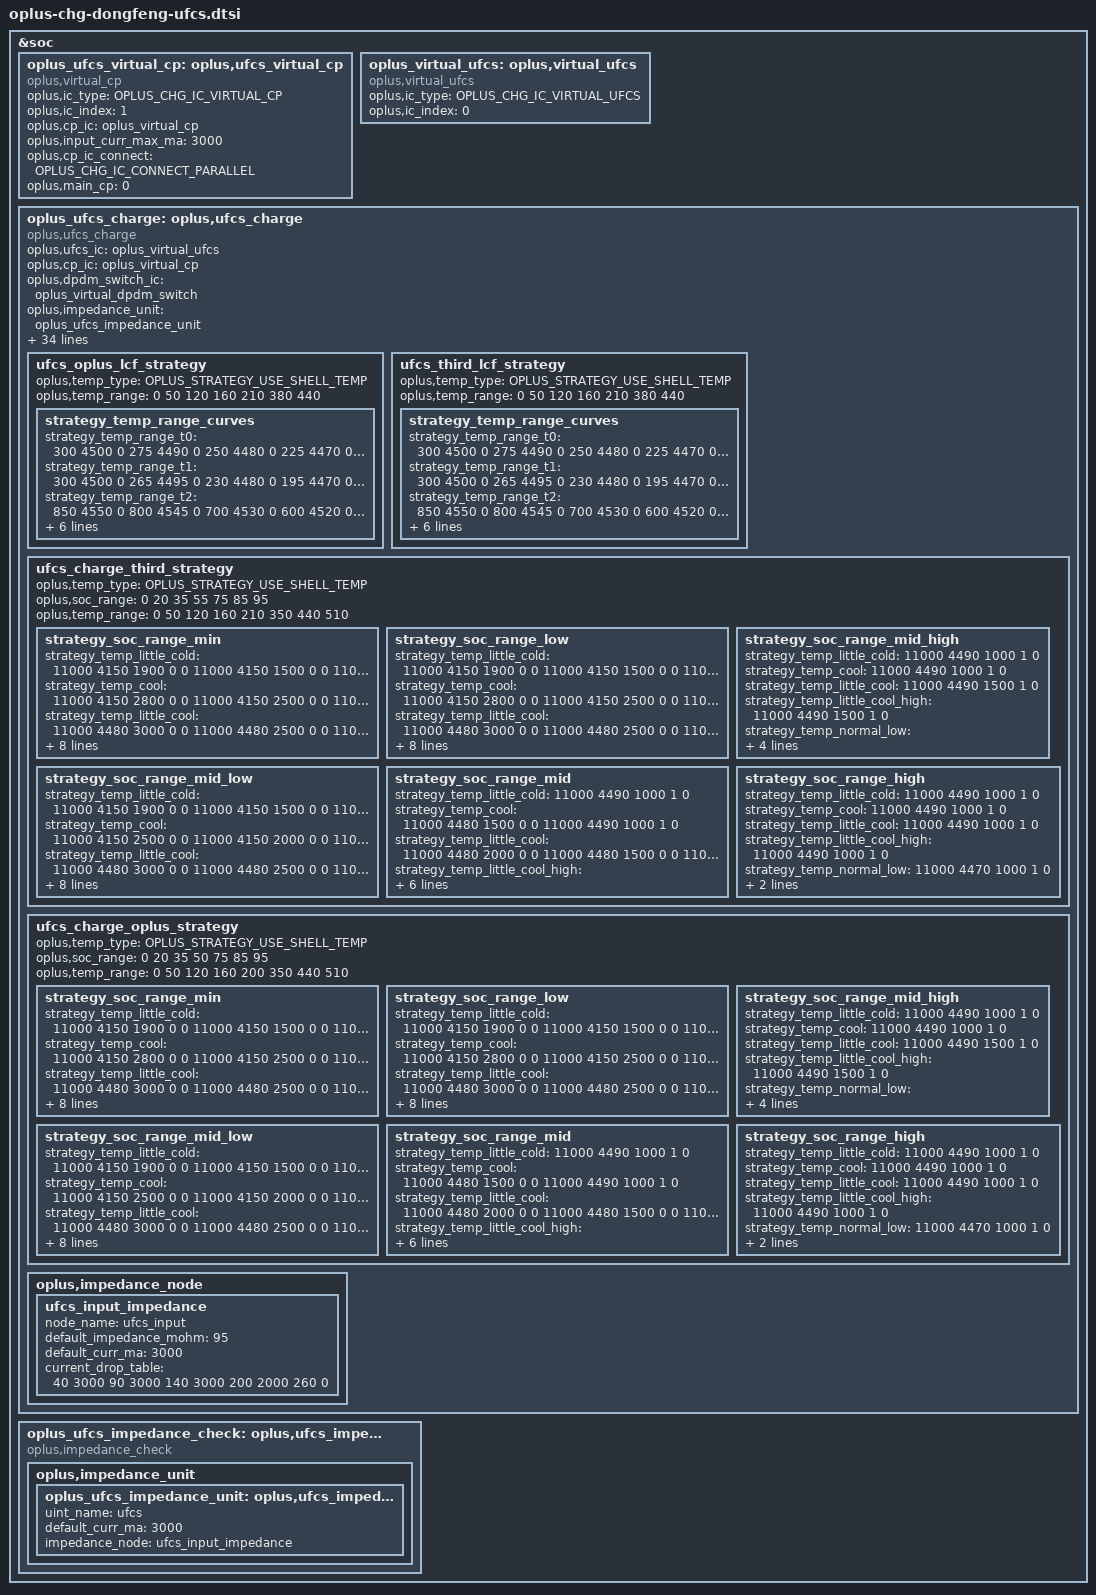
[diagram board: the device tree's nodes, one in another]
//ifdef OPLUS_FEATURE_CHG_BASIC
//BSP.CHG.Basic, 2024/08/03,  Add for charging

#include <dt-bindings/iio/qcom,spmi-adc5-gen3-pmxr2230.h>
#include <dt-bindings/iio/qcom,spmi-adc5-gen3-pmiv0104.h>
#include <dt-bindings/iio/qcom,spmi-adc5-gen3-pmk8550.h>

#include "../oplus-chg-8650.h.dtsi"

&soc {
	oplus_ufcs_virtual_cp: oplus,ufcs_virtual_cp {
		compatible = "oplus,virtual_cp";

		oplus,ic_type = <OPLUS_CHG_IC_VIRTUAL_CP>;
		oplus,ic_index = <1>;

		oplus,cp_ic = <&oplus_virtual_cp>;
		oplus,input_curr_max_ma = <3000>;

		oplus,cp_ic_connect = <OPLUS_CHG_IC_CONNECT_PARALLEL>;
		oplus,main_cp = <0>;
	};

	oplus_virtual_ufcs: oplus,virtual_ufcs {
		compatible = "oplus,virtual_ufcs";

		oplus,ic_type = <OPLUS_CHG_IC_VIRTUAL_UFCS>;
		oplus,ic_index = <0>;
	};

	oplus_ufcs_charge: oplus,ufcs_charge {
		compatible = "oplus,ufcs_charge";
		oplus,ufcs_ic = <&oplus_virtual_ufcs>;
		oplus,cp_ic = <&oplus_virtual_cp>;
		oplus,dpdm_switch_ic = <&oplus_virtual_dpdm_switch>;

		oplus,impedance_unit = <&oplus_ufcs_impedance_unit>;

		oplus,target_vbus_mv = <11000>;
		oplus,curr_max_ma = <3000>;

		oplus,ufcs_warm_allow_vol = <4000>;
		oplus,ufcs_warm_allow_soc = <55>;
		oplus,ufcs_strategy_normal_current = <3000>;//6A
		oplus,ufcs_over_high_or_low_current = <3000>;
		oplus,ufcs_timeout_third = <15068>;
		oplus,ufcs_timeout_oplus = <15068>;
		oplus,ufcs_ibat_over_third = <7400>;
		oplus,ufcs_ibat_over_oplus = <7400>;
		oplus,ufcs_full_cool_sw_vbat = <4490>;
		oplus,ufcs_full_normal_sw_vbat = <4490>;
		oplus,ufcs_full_normal_hw_vbat = <4500>;
		oplus,ufcs_full_ffc_vbat = <4485>;
		oplus,ufcs_full_warm_vbat = <4130>;
		oplus,ufcs_full_cool_sw_vbat_third = <4490>;
		oplus,ufcs_full_normal_sw_vbat_third= <4490>;
		oplus,ufcs_full_normal_hw_vbat_third = <4500>;
		oplus,ufcs_current_change_timeout = <100>;
		oplus,ufcs_strategy_batt_high_temp = <410 420 430 400 410 420>;
		oplus,ufcs_strategy_high_current = <3000 3000 2000 3000 3000 3000>;
		oplus,ufcs_little_cool_high_temp = <210>;
		oplus,curve_strategy_name = "pps_ufcs_curve_v2";
		oplus_spec,ufcs_high_soc = <95>;
		oplus,ufcs_charge_strategy_soc = <0 20 35 55 75 85 95>;
		oplus,ufcs_charge_strategy_temp = <0 50 120 160 350 440 510>;

		oplus,plc_strategy-data = <&oplus_ufcs_step_strategy &third_ufcs_simple_strategy>;
		oplus,plc_strategy-names = "default", "third";

		ufcs_oplus_lcf_strategy {
			oplus,temp_type = <OPLUS_STRATEGY_USE_SHELL_TEMP>;
			oplus,temp_range = <0 50 120 160 210 380 440>;
			strategy_temp_range_curves {
				strategy_temp_range_t0 =	<300 4500 0
								275 4490 0
								250 4480 0
								225 4470 0
								200 4460 1>;
				strategy_temp_range_t1 =	<300 4500 0
								265 4495 0
								230 4480 0
								195 4470 0
								160 4460 1>;
				strategy_temp_range_t2 =	<850 4550 0
								800 4545 0
								700 4530 0
								600 4520 0
								450 4510 1>;
				strategy_temp_range_t3 =	<1350 4550 0
								1300 4545 0
								1200 4530 0
								1100  4520 0
								950  4510 1>;
				strategy_temp_range_t4 =	<1350 4550 0
								1300 4545 0
								1200 4530 0
								1100 4520 0
								950 4510 1>;
				strategy_temp_range_t5 =	<2100 4550 0
								2050 4545 0
								1950 4530 0
								1850 4520 0
								1700 4510 1>;
			};
		};
		ufcs_third_lcf_strategy {
			oplus,temp_type = <OPLUS_STRATEGY_USE_SHELL_TEMP>;
			oplus,temp_range = <0 50 120 160 210 380 440>;
			strategy_temp_range_curves {
				strategy_temp_range_t0 =	<300 4500 0
								275 4490 0
								250 4480 0
								225 4470 0
								200 4460 1>;
				strategy_temp_range_t1 =	<300 4500 0
								265 4495 0
								230 4480 0
								195 4470 0
								160 4460 1>;
				strategy_temp_range_t2 =	<850 4550 0
								800 4545 0
								700 4530 0
								600 4520 0
								450 4510 1>;
				strategy_temp_range_t3 =	<1350 4550 0
								1300 4545 0
								1200 4530 0
								1100  4520 0
								950  4510 1>;
				strategy_temp_range_t4 =	<1350 4550 0
								1300 4545 0
								1200 4530 0
								1100 4520 0
								950 4510 1>;
				strategy_temp_range_t5 =	<2100 4550 0
								2050 4545 0
								1950 4530 0
								1850 4520 0
								1700 4510 1>;
			};
		};

		ufcs_charge_third_strategy {
			oplus,temp_type = <OPLUS_STRATEGY_USE_SHELL_TEMP>;
			oplus,soc_range = <0 20 35 55 75 85 95>;
			oplus,temp_range = <0 50 120 160 210 350 440 510>;

			strategy_soc_range_min {
				strategy_temp_little_cold =	<11000 4150 1900 0 0
								11000 4150 1500 0 0
								11000 4480 1350 0 0
								11000 4490 1000 1 0>;
				strategy_temp_cool =		<11000 4150 2800 0 0
								11000 4150 2500 0 0
								11000 4150 2000 0 0
								11000 4480 1900 0 0
								11000 4480 1500 0 0
								11000 4490 1000 1 0>;
				strategy_temp_little_cool =	<11000 4480 3000 0 0
								11000 4480 2500 0 0
								11000 4480 2200 0 0
								11000 4480 2000 0 0
								11000 4480 1500 0 0
								11000 4490 1000 1 0>;
				strategy_temp_little_cool_high = <11000 4480 3000 0 0
								11000 4480 2500 0 0
								11000 4480 2200 0 0
								11000 4480 2000 0 0
								11000 4480 1500 0 0
								11000 4490 1000 1 0>;
				strategy_temp_normal_low =	<11000 4480 3000 0 0
								11000 4480 2500 0 0
								11000 4480 2200 0 0
								11000 4480 2000 0 0
								11000 4480 1500 0 0
								11000 4490 1000 1 0>;
				strategy_temp_normal_high =	<11000 4460 3000 0 0
								11000 4460 2500 0 0
								11000 4460 2200 0 0
								11000 4460 2000 0 0
								11000 4460 1500 0 0
								11000 4470 1000 1 0>;
				strategy_temp_warm =		<11000 4120 1600 0 0
								11000 4120 1500 0 0
								11000 4130 1000 1 0>;
			};
			strategy_soc_range_low {
				strategy_temp_little_cold =	<11000 4150 1900 0 0
								11000 4150 1500 0 0
								11000 4480 1350 0 0
								11000 4490 1000 1 0>;
				strategy_temp_cool =		<11000 4150 2800 0 0
								11000 4150 2500 0 0
								11000 4150 2000 0 0
								11000 4480 1900 0 0
								11000 4480 1500 0 0
								11000 4490 1000 1 0>;
				strategy_temp_little_cool =	<11000 4480 3000 0 0
								11000 4480 2500 0 0
								11000 4480 2200 0 0
								11000 4480 2000 0 0
								11000 4480 1500 0 0
								11000 4490 1000 1 0>;
				strategy_temp_little_cool_high = <11000 4480 3000 0 0
								11000 4480 2500 0 0
								11000 4480 2200 0 0
								11000 4480 2000 0 0
								11000 4480 1500 0 0
								11000 4490 1000 1 0>;
				strategy_temp_normal_low =	<11000 4480 3000 0 0
								11000 4480 2500 0 0
								11000 4480 2200 0 0
								11000 4480 2000 0 0
								11000 4480 1500 0 0
								11000 4490 1000 1 0>;
				strategy_temp_normal_high =	<11000 4460 3000 0 0
								11000 4460 2500 0 0
								11000 4460 2200 0 0
								11000 4460 2000 0 0
								11000 4460 1500 0 0
								11000 4470 1000 1 0>;
				strategy_temp_warm =		<11000 4120 1600 0 0
								11000 4120 1500 0 0
								11000 4130 1000 1 0>;
			};
			strategy_soc_range_mid_low {
				strategy_temp_little_cold =	<11000 4150 1900 0 0
								11000 4150 1500 0 0
								11000 4480 1350 0 0
								11000 4490 1000 1 0>;
				strategy_temp_cool =		<11000 4150 2500 0 0
								11000 4150 2000 0 0
								11000 4480 1900 0 0
								11000 4480 1500 0 0
								11000 4490 1000 1 0>;
				strategy_temp_little_cool =	<11000 4480 3000 0 0
								11000 4480 2500 0 0
								11000 4480 2200 0 0
								11000 4480 2000 0 0
								11000 4480 1500 0 0
								11000 4490 1000 1 0>;
				strategy_temp_little_cool_high = <11000 4480 3000 0 0
								11000 4480 2500 0 0
								11000 4480 2200 0 0
								11000 4480 2000 0 0
								11000 4480 1500 0 0
								11000 4490 1000 1 0>;
				strategy_temp_normal_low =	<11000 4480 3000 0 0
								11000 4480 2500 0 0
								11000 4480 2200 0 0
								11000 4480 2000 0 0
								11000 4480 1500 0 0
								11000 4490 1000 1 0>;
				strategy_temp_normal_high =	<11000 4460 3000 0 0
								11000 4460 2500 0 0
								11000 4460 2200 0 0
								11000 4460 2000 0 0
								11000 4460 1500 0 0
								11000 4470 1000 1 0>;
				strategy_temp_warm =		<11000 4120 1600 0 0
								11000 4120 1500 0 0
								11000 4130 1000 1 0>;
			};
			strategy_soc_range_mid {
				strategy_temp_little_cold =	<11000 4490 1000 1 0>;
				strategy_temp_cool =		<11000 4480 1500 0 0
								11000 4490 1000 1 0>;
				strategy_temp_little_cool =	<11000 4480 2000 0 0
								11000 4480 1500 0 0
								11000 4490 1000 1 0>;
				strategy_temp_little_cool_high = <11000 4480 2000 0 0
								11000 4480 1500 0 0
								11000 4490 1000 1 0>;
				strategy_temp_normal_low =	<11000 4480 2000 0 0
								11000 4480 1500 0 0
								11000 4490 1000 1 0>;
				strategy_temp_normal_high =	<11000 4460 2000 0 0
								11000 4460 1500 0 0
								11000 4470 1000 1 0>;
				strategy_temp_warm =		<11000 4130 1000 1 0>;
			};
			strategy_soc_range_mid_high {
				strategy_temp_little_cold =	<11000 4490 1000 1 0>;
				strategy_temp_cool =		<11000 4490 1000 1 0>;
				strategy_temp_little_cool =	<11000 4490 1500 1 0>;
				strategy_temp_little_cool_high = <11000 4490 1500 1 0>;
				strategy_temp_normal_low =	<11000 4480 1500 0 0
								11000 4490 1000 1 0>;
				strategy_temp_normal_high =	<11000 4460 1500 0 0
								11000 4470 1000 1 0>;
				strategy_temp_warm =		<11000 4130 1000 1 0>;
			};
			strategy_soc_range_high {
				strategy_temp_little_cold =	<11000 4490 1000 1 0>;
				strategy_temp_cool =		<11000 4490 1000 1 0>;
				strategy_temp_little_cool =	<11000 4490 1000 1 0>;
				strategy_temp_little_cool_high = <11000 4490 1000 1 0>;
				strategy_temp_normal_low =	<11000 4470 1000 1 0>;
				strategy_temp_normal_high =	<11000 4470 1000 1 0>;
				strategy_temp_warm =		<11000 4130 1000 1 0>;
			};
		};

		ufcs_charge_oplus_strategy {
			oplus,temp_type = <OPLUS_STRATEGY_USE_SHELL_TEMP>;
			oplus,soc_range = <0 20 35 50 75 85 95>;
			oplus,temp_range = <0 50 120 160 200 350 440 510>;
			strategy_soc_range_min {
				strategy_temp_little_cold =	<11000 4150 1900 0 0
								11000 4150 1500 0 0
								11000 4480 1350 0 0
								11000 4490 1000 1 0>;
				strategy_temp_cool =		<11000 4150 2800 0 0
								11000 4150 2500 0 0
								11000 4150 2000 0 0
								11000 4480 1900 0 0
								11000 4480 1500 0 0
								11000 4490 1000 1 0>;
				strategy_temp_little_cool =	<11000 4480 3000 0 0
								11000 4480 2500 0 0
								11000 4480 2200 0 0
								11000 4480 2000 0 0
								11000 4480 1500 0 0
								11000 4490 1000 1 0>;
				strategy_temp_little_cool_high = <11000 4480 3000 0 0
								11000 4480 2500 0 0
								11000 4480 2200 0 0
								11000 4480 2000 0 0
								11000 4480 1500 0 0
								11000 4490 1000 1 0>;
				strategy_temp_normal_low =	<11000 4480 3000 0 0
								11000 4480 2500 0 0
								11000 4480 2200 0 0
								11000 4480 2000 0 0
								11000 4480 1500 0 0
								11000 4490 1000 1 0>;
				strategy_temp_normal_high =	<11000 4460 3000 0 0
								11000 4460 2500 0 0
								11000 4460 2200 0 0
								11000 4480 2000 0 0
								11000 4460 1500 0 0
								11000 4470 1000 1 0>;
				strategy_temp_warm =		<11000 4120 1600 0 0
								11000 4120 1500 0 0
								11000 4130 1000 1 0>;
			};
			strategy_soc_range_low {
				strategy_temp_little_cold =	<11000 4150 1900 0 0
								11000 4150 1500 0 0
								11000 4480 1350 0 0
								11000 4490 1000 1 0>;
				strategy_temp_cool =		<11000 4150 2800 0 0
								11000 4150 2500 0 0
								11000 4150 2000 0 0
								11000 4480 1900 0 0
								11000 4480 1500 0 0
								11000 4490 1000 1 0>;
				strategy_temp_little_cool =	<11000 4480 3000 0 0
								11000 4480 2500 0 0
								11000 4480 2200 0 0
								11000 4480 2000 0 0
								11000 4480 1500 0 0
								11000 4490 1000 1 0>;
				strategy_temp_little_cool_high = <11000 4480 3000 0 0
								11000 4480 2500 0 0
								11000 4480 2200 0 0
								11000 4480 2000 0 0
								11000 4480 1500 0 0
								11000 4490 1000 1 0>;
				strategy_temp_normal_low =	<11000 4480 3000 0 0
								11000 4480 2500 0 0
								11000 4480 2200 0 0
								11000 4480 2000 0 0
								11000 4480 1500 0 0
								11000 4490 1000 1 0>;
				strategy_temp_normal_high =	<11000 4460 3000 0 0
								11000 4460 2500 0 0
								11000 4460 2200 0 0
								11000 4460 2000 0 0
								11000 4460 1500 0 0
								11000 4470 1000 1 0>;
				strategy_temp_warm =		<11000 4120 1600 0 0
								11000 4120 1500 0 0
								11000 4130 1000 1 0>;
			};
			strategy_soc_range_mid_low {
				strategy_temp_little_cold =	<11000 4150 1900 0 0
								11000 4150 1500 0 0
								11000 4480 1350 0 0
								11000 4490 1000 1 0>;
				strategy_temp_cool =		<11000 4150 2500 0 0
								11000 4150 2000 0 0
								11000 4480 1900 0 0
								11000 4480 1500 0 0
								11000 4490 1000 1 0>;
				strategy_temp_little_cool =	<11000 4480 3000 0 0
								11000 4480 2500 0 0
								11000 4480 2200 0 0
								11000 4480 2000 0 0
								11000 4480 1500 0 0
								11000 4490 1000 1 0>;
				strategy_temp_little_cool_high = <11000 4480 3000 0 0
								11000 4480 2500 0 0
								11000 4480 2200 0 0
								11000 4480 2000 0 0
								11000 4480 1500 0 0
								11000 4490 1000 1 0>;
				strategy_temp_normal_low =	<11000 4480 3000 0 0
								11000 4480 2500 0 0
								11000 4480 2200 0 0
								11000 4480 2000 0 0
								11000 4480 1500 0 0
								11000 4490 1000 1 0>;
				strategy_temp_normal_high =	<11000 4460 3000 0 0
								11000 4460 2500 0 0
								11000 4460 2200 0 0
								11000 4460 2000 0 0
								11000 4460 1500 0 0
								11000 4470 1000 1 0>;
				strategy_temp_warm =		<11000 4120 1600 0 0
								11000 4120 1500 0 0
								11000 4130 1000 1 0>;
			};
			strategy_soc_range_mid {
				strategy_temp_little_cold =	<11000 4490 1000 1 0>;
				strategy_temp_cool =		<11000 4480 1500 0 0
								11000 4490 1000 1 0>;
				strategy_temp_little_cool =	<11000 4480 2000 0 0
								11000 4480 1500 0 0
								11000 4490 1000 1 0>;
				strategy_temp_little_cool_high = <11000 4480 2000 0 0
								11000 4480 1500 0 0
								11000 4490 1000 1 0>;
				strategy_temp_normal_low =	<11000 4480 2000 0 0
								11000 4480 1500 0 0
								11000 4490 1000 1 0>;
				strategy_temp_normal_high =	<11000 4460 2000 0 0
								11000 4460 1500 0 0
								11000 4470 1000 1 0>;
				strategy_temp_warm =		<11000 4130 1000 1 0>;
			};
			strategy_soc_range_mid_high {
				strategy_temp_little_cold =	<11000 4490 1000 1 0>;
				strategy_temp_cool =		<11000 4490 1000 1 0>;
				strategy_temp_little_cool =	<11000 4490 1500 1 0>;
				strategy_temp_little_cool_high = <11000 4490 1500 1 0>;
				strategy_temp_normal_low =	<11000 4480 1500 0 0
								11000 4490 1000 1 0>;
				strategy_temp_normal_high =	<11000 4460 1500 0 0
								11000 4470 1000 1 0>;
				strategy_temp_warm =		<11000 4130 1000 1 0>;
			};
			strategy_soc_range_high {
				strategy_temp_little_cold =	<11000 4490 1000 1 0>;
				strategy_temp_cool =		<11000 4490 1000 1 0>;
				strategy_temp_little_cool =	<11000 4490 1000 1 0>;
				strategy_temp_little_cool_high = <11000 4490 1000 1 0>;
				strategy_temp_normal_low =	<11000 4470 1000 1 0>;
				strategy_temp_normal_high =	<11000 4470 1000 1 0>;
				strategy_temp_warm =		<11000 4130 1000 1 0>;
			};
		};

		oplus,impedance_node {
			ufcs_input_impedance: ufcs_input_impedance {
				node_name = "ufcs_input";
				default_impedance_mohm = <95>;
				default_curr_ma = <3000>;
				current_drop_table = <
					40  3000
					90  3000
					140  3000
					200  2000
					260  0
				>;
			};
		};
	};

	oplus_ufcs_impedance_check: oplus,ufcs_impedance_check {
		compatible = "oplus,impedance_check";

		oplus,impedance_unit {
			oplus_ufcs_impedance_unit: oplus,ufcs_impedance_unit {
				uint_name = "ufcs";
				default_curr_ma = <3000>;
				impedance_node = <&ufcs_input_impedance>;
			};
		};
	};
};
